# RL6678_IP_SVD register map
Vendor: Realtek
Registers are 32-bit, read-write, reset 0x0 unless marked. A register's access mark holds for its fields unless they carry their own. Offsets are from the block's base; [hi:lo] are bit positions; {n}, {i} and the like mark numbered series.

## LCDC_REG
Base 0x400D8000
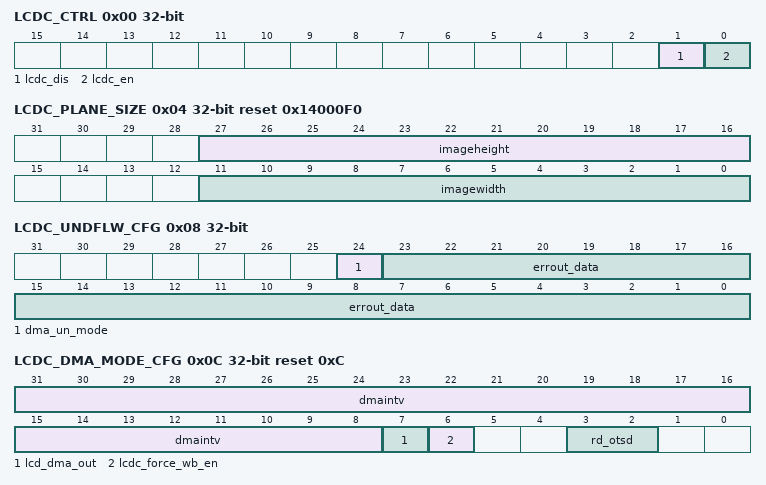
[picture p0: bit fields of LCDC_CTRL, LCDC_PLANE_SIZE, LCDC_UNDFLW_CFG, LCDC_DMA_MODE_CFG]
0x00 LCDC_CTRL — LCDC control register
  [1] lcdc_dis — Disable LCDC instantly. Reset LCDC internal states and disable LCDC then clear both this bit and LCDCEN.
  [0] lcdc_en — Write 1 to enable LCDC.
0x04 LCDC_PLANE_SIZE reset 0x14000F0
  [27:16] imageheight — The height of image (Y-channel based), the min. value is 0x1.
  [11:0] imagewidth — The width of image (X-channel based), the min. value is 0x1. *For LCD, it means pixel number per line.
0x08 LCDC_UNDFLW_CFG — LCDC underflow configuration register
  [24] dma_un_mode — *0:Output last data *1:Output erroutdata
  [23:0] errout_data — Output data when DMA FIFO underflow occurred. (directly mapping to output D[23:0])
0x0C LCDC_DMA_MODE_CFG access per field reset 0xC — LCDC DMA mode configuration register
  [31:8] dmaintv ro — The interval cycle count between two DMA requests. (for debug) Unit: bus clock cycle.
  [7] lcd_dma_out rw — Secondary RGB output port enabled, the blended data of entire image will be written back to memory. The destination address is defined in LDCD_IMG_DEST_ADDR. (for debug)
  [6] lcdc_force_wb_en rw — force lcdc write back memory without mipi ask signal, please tie 0 when lcdc function running. (for debug)
  [3:2] rd_otsd rw — The value of read outstanding -1, for DMA burst size configuration
0x10 LCDC_SHW_RLD_CFG — LCDC shadow reload configuration register
  [0] VBR — vertical blanking reload. This bit is set by software and cleared only by hardware after reload (it cannot be cleared through register write once it is set). 0: no effect 1: The shadow registers are reloaded during the vertical blanking period (at the beginning of the first line after the active display area).
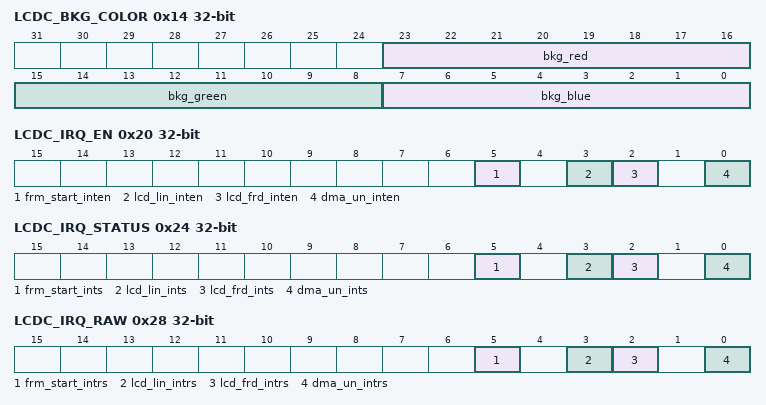
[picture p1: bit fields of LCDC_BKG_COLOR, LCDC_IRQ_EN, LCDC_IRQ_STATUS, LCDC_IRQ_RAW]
0x14 LCDC_BKG_COLOR — LCDC background color register
  [23:16] bkg_red — Default Color Red
  [15:8] bkg_green — Default Color Green
  [7:0] bkg_blue — Default Color Blue
0x18 LCDC_SEC_DEST_ADDR — LCDC second image destination address register
  [31:0] img_dest_addr — Image DMA destination address. (for debug)
0x1C LCDC_DEBUG_STATUS ro — Debug signal
  [31:0] lcdc_debug_states — LCDC critial signal for debug
0x20 LCDC_IRQ_EN — LCDC interrupt enable register
  [5] frm_start_inten — DMA Frame start interrupt Enable. This bit can be set and cleared by software. * 0: DMA Frame start interrupt disable * 1: DMA Frame start interrupt enable
  [3] lcd_lin_inten — Line Interrupt Enable. This bit can be set and cleared by software. * 0: Line interrupt disable * 1: Line Interrupt enable
  [2] lcd_frd_inten — LCD refresh frame done interrupt enable
  [0] dma_un_inten — DMA FIFO underflow interrupt enable
0x24 LCDC_IRQ_STATUS ro — LCDC interrupt status register
  [5] frm_start_ints — DMA frame start interrupt status. Write 1 to clear it. * 0: No DMA frame start interrupt generated * 1: A DMA frame start interrupt is generated
  [3] lcd_lin_ints — Line Interrupt status. Write 1 to clear it. * 0: No Line interrupt generated * 1: A Line interrupt is generated, when a programmed line is reached Note: When this bit is set and DMA fetches the first pixel data of the specified line number from frame buffer, the line interrupt happens. The line number depends on LCDC_LINE_INT_POS register value.
  [2] lcd_frd_ints — LCD refresh frame done interrupt status. Write 1 to clear it. * 0: No LCD refresh frame done interrupt generated. * 1: This interrupt generated, when sending LCD frame done. Note: When this bit is set and DMA fetch the last pixel data from frame buffer, the After LCD refresh frame done, interrupt happens.
  [0] dma_un_ints — DMA FIFO underflow interrupt status. Write 1 to clear it. * 0: No DMA FIFO underflow interrupt generated * 1: Interrupt generated when DMA FIFO underflow happens
0x28 LCDC_IRQ_RAW ro — LCDC raw interrupt register
  [5] frm_start_intrs — DMA frame start raw interrupt status. No matter DMA frame start interrupt is enabled or disabled, this bit is set when DMA frame start interrupt happens. Writting 1 to the FRM_START_INTS field in register LCDC_IRQ_STATUS is to clear this bit.
  [3] lcd_lin_intrs — Line Interrupt raw status. No matter the line interrupt is enabled or disabled, this bit is set when line interrupt happens. Writting 1 to the LCD_LIN_INTS field in register LCDC_IRQ_STATUS is to clear this bit.
  [2] lcd_frd_intrs — LCD refresh frame done raw interrupt status. No matter the refresh done interrupt is enabled or disabled, this bit is set when refresh done interrupt happens. Writting 1 to the LCD_FRD_INTS field in register LCDC_IRQ_STATUS is to clear this bit.
  [0] dma_un_intrs — DMA FIFO underflow raw interrupt status. When LCDC DMA FIFO under flow event happens, this bit is set. Write 1 to the DMAUNINTS field in register LCDC_IRQ_STATUS to clear this bit.
0x2C LCDC_LINE_INT_POS — LCDC line interrupt position register
  [11:0] line_int_pos — Line Interrupt Position These bits configure the line interrupt position.
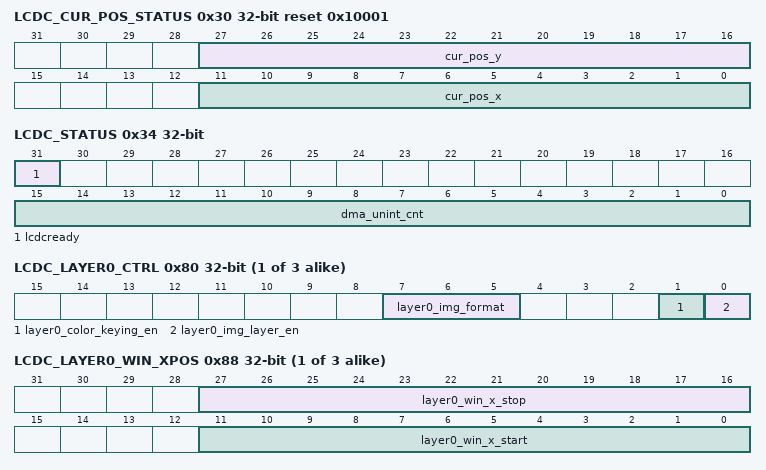
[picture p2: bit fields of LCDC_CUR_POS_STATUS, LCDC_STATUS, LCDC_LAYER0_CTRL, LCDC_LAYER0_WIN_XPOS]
0x30 LCDC_CUR_POS_STATUS ro reset 0x10001 — Display current position
  [27:16] cur_pos_y — Current Y Position These bits return the current Y position.
  [11:0] cur_pos_x — Current X Position These bits return the current X position.
0x34 LCDC_STATUS ro — Underflow times
  [31] lcdcready — LCDC is ready to operate with VO interface after LCDC is enabled.
  [15:0] dma_unint_cnt — DMA FIFO underflow interrupt count
{0x80+0x20*i} LCDC_LAYER{i}_CTRL (i=0..2)
  [7:5] layer{i}_img_format — Image layer data format, it supports the following values: *000: ARGB8888 *001: RGB888 *010: RGB565 *011: ARGB1555 *100: ARGB4444 *101: RGB666 *110: ARGB8666 *Others: Reserved
  [1] layer{i}_color_keying_en — Color Keying Enable *0: Color Keying disable *1: Color Keying enable
  [0] layer{i}_img_layer_en — Image layer enable *0: Disable *1: Enable
{0x84+0x20*i} LCDC_LAYER{i}_BASE_ADDR (i=0..2)
  [31:0] layer{i}_img_base_addr — Image layer DMA source address. After a frame refresh done, hardware loads the newer base address from this register automatically.
{0x88+0x20*i} LCDC_LAYER{i}_WIN_XPOS (i=0..2)
  [27:16] layer{i}_win_x_stop — Window Horizontal Stop Position These bits configure the last visible pixel of a line of the layer window. Please make sure it is in work plane,the min value is 1. Ex:32*32 picture: the x start postion is 1 and x stop postion is 32.
  [11:0] layer{i}_win_x_start — Window Horizontal Start Position These bits configure the first visible pixel of a line of the layer window. Please make sure it is in work plane,the min value is 1. Ex:32*32 picture: the x start postion is 1 and x stop postion is 32. Layer size(x*y) must >=10 pixel
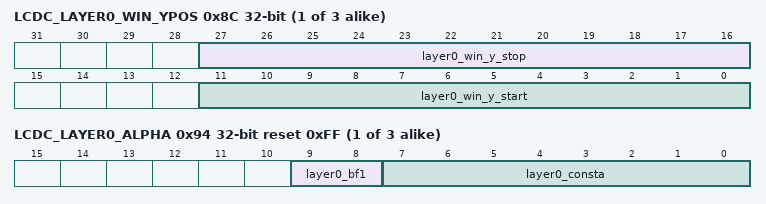
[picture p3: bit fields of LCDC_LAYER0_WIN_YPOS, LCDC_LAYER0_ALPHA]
{0x8C+0x20*i} LCDC_LAYER{i}_WIN_YPOS (i=0..2)
  [27:16] layer{i}_win_y_stop — Window Vertical Stop Position These bits configure the last visible line of the layer window. Please make sure it is in work plane,the min value is 1. Ex:32*32 picture: the y start postion is 1 and y stop postion is 32.
  [11:0] layer{i}_win_y_start — Window Vertical Start Position These bits configure the first visible line of the layer window. Please make sure it is in work plane,the min value is 1. Ex:32*32 picture: the y start postion is 1 and y stop postion is 32. Layer size(x*y) must >=10 pixel
{0x90+0x20*i} LCDC_LAYER{i}_COLOR_KEY (i=0..2)
  [23:0] layer{i}_color_key_value — Color Key value depends on the selected input color format
{0x94+0x20*i} LCDC_LAYER{i}_ALPHA reset 0xFF (i=0..2)
  [9:8] layer{i}_bf1 — Blending factor 1. This field selects the blending factor F1. *00: Constant alpha *01: Pixel alpha x constant alpha *Others : Reserved
  [7:0] layer{i}_consta — Constant alpha. This field configures the constant alpha used for blending. The constant alpha is divided by 256 by hardware. The max. value of constant is FF, so when the constant alpha arrives the max. value, it is identified as 1.
